# CC2340R5 register map
File version: 1.0
CPU: CM0P 1.0, other endian, MPU, FPU, 3 interrupt priority bits
Registers are 32-bit, read-write, reset 0x0 unless marked. A register's access mark holds for its fields unless they carry their own. Offsets are from the block's base; [hi:lo] are bit positions; {n}, {i} and the like mark numbered series; 'fields as' and 'values as' point back to an identical list.

## PMUD
Base 0x40006000
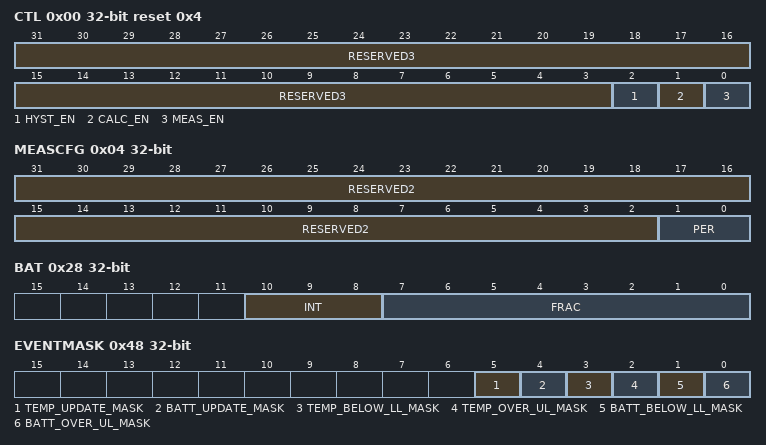
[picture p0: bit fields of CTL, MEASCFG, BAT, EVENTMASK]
0x00 CTL reset 0x4 — Internal. Only to be used through TI provided API.
  [31:3] RESERVED3 ro — [31:3] Internal. Only to be used through TI provided API.
  [2] HYST_EN — [2:2] Internal. Only to be used through TI provided API.
  [1] CALC_EN — [1:1] Internal. Only to be used through TI provided API.
  [0] MEAS_EN — [0:0] Internal. Only to be used through TI provided API.
0x04 MEASCFG — Internal. Only to be used through TI provided API.
  [31:2] RESERVED2 ro — [31:2] Internal. Only to be used through TI provided API.
  [1:0] PER — [1:0] Internal. Only to be used through TI provided API.
    3=_32CYC (Internal. Only to be used through TI provided API.); 2=_16CYC (Internal. Only to be used through TI provided API.); 1=_8CYC (Internal. Only to be used through TI provided API.); 0=CONT (Internal. Only to be used through TI provided API.)
0x08 COMPTEST — Enable BATMON comparator test mode. Note: This register is write-protected based on global lock signal from SYS0 on production devices.
  [0] EN — [0:0] Enable test mode.
    1=ENABLE; 0=DISABLE
0x28 BAT — Last Measured Battery Voltage This register may be read while BATUPD.STAT = 1
  [10:8] INT ro — [10:8] Integer part: 0x0: 0V + fractional part ... 0x3: 3V + fractional part 0x4: 4V + fractional part
  [7:0] FRAC ro — [7:0] Fractional part, standard binary fractional encoding. 0x00: .0V ... 0x20: 1/8 = .125V 0x40: 1/4 = .25V 0x80: 1/2 = .5V ... 0xA0: 1/2 + 1/8 = .625V ... 0xFF: Max
0x2C BATUPD — Battery Update Indicates BAT Updates
  [0] STAT — [0:0] 0: No update since last clear 1: New battery voltage is present. Write 1 to clear the status.
0x30 TEMP — Temperature Last Measured Temperature in Degrees Celsius This register may be read while TEMPUPD.STAT = 1.
  [16:8] INT ro — [16:8] Integer part (signed) of temperature value. Total value = INTEGER + FRACTIONAL 2's complement encoding 0x100: Min value 0x1D8: -40C 0x1FF: -1C 0x00: 0C 0x1B: 27C 0x55: 85C 0xFF: Max value
0x34 TEMPUPD — Temperature Update Indicates TEMP Updates
  [0] STAT — [0:0] 0: No update since last clear 1: New temperature is present. Write 1 to clear the status.
0x38 COMPTESTOUT — BATMON comparator test mode output.
  [0] STAT ro — [0:0] Comparator output in test mode.
    1=HIGH; 0=LOW
0x48 EVENTMASK
  [5] TEMP_UPDATE_MASK — [5:5] 1: EVENT.TEMP_UPDATE contributes to combined event from BATMON 0: EVENT.TEMP_UPDATE does not contribute to combined event from BATMON
  [4] BATT_UPDATE_MASK — [4:4] 1: EVENT.BATT_UPDATE contributes to combined event from BATMON 0: EVENT.BATT_UPDATE does not contribute to combined event from BATMON
  [3] TEMP_BELOW_LL_MASK — [3:3] 1: EVENT.TEMP_BELOW_LL contributes to combined event from BATMON 0: EVENT.TEMP_BELOW_LL does not contribute to combined event from BATMON
  [2] TEMP_OVER_UL_MASK — [2:2] 1: EVENT.TEMP_OVER_UL contributes to combined event from BATMON 0: EVENT.TEMP_OVER_UL does not contribute to combined event from BATMON
  [1] BATT_BELOW_LL_MASK — [1:1] 1: EVENT.BATT_BELOW_LL contributes to combined event from BATMON 0: EVENT.BATT_BELOW_LL does not contribute to combined event from BATMON
  [0] BATT_OVER_UL_MASK — [0:0] 1: EVENT.BATT_OVER_UL contributes to combined event from BATMON 0: EVENT.BATT_OVER_UL does not contribute to combined event from BATMON
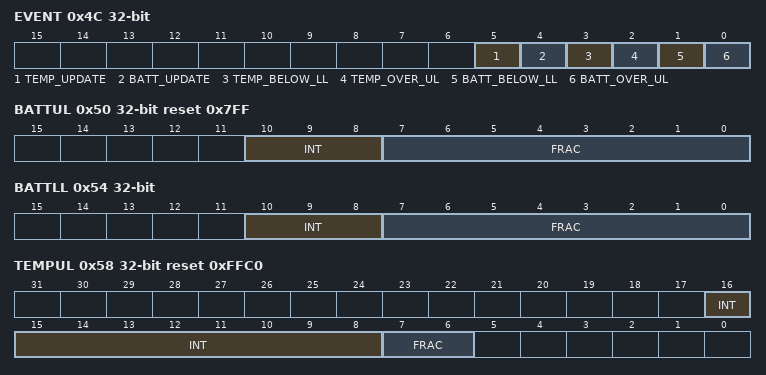
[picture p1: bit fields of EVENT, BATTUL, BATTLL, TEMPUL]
0x4C EVENT
  [5] TEMP_UPDATE — [5:5] Alias to TEMPUPD.STAT
  [4] BATT_UPDATE — [4:4] Alias to BATUPD.STAT
  [3] TEMP_BELOW_LL — [3:3] Read: 1: Temperature level is below the lower limit set by TEMPLL. 0: Temperature level is not below the lower limit set by TEMPLL. Write: 1: Clears the flag 0: No change in the flag
  [2] TEMP_OVER_UL — [2:2] Read: 1: Temperature level is above the upper limit set by TEMPUL. 0: Temperature level is not above the upper limit set by TEMPUL. Write: 1: Clears the flag 0: No change in the flag
  [1] BATT_BELOW_LL — [1:1] Read: 1: Battery level is below the lower limit set by BATTLL. 0: Battery level is not below the lower limit set by BATTLL. Write: 1: Clears the flag 0: No change in the flag
  [0] BATT_OVER_UL — [0:0] Read: 1: Battery level is above the upper limit set by BATTUL. 0: Battery level is not above the upper limit set by BATTUL. Write: 1: Clears the flag 0: No change in the flag
0x50 BATTUL reset 0x7FF — Battery Upper Limit
  [10:8] INT — [10:8] Integer part: 0x0: 0V + fractional part ... 0x3: 3V + fractional part 0x4: 4V + fractional part
  [7:0] FRAC — [7:0] Fractional part, standard binary fractional encoding. 0x00: .0V ... 0x20: 1/8 = .125V 0x40: 1/4 = .25V 0x80: 1/2 = .5V ... 0xA0: 1/2 + 1/8 = .625V ... 0xFF: Max
0x54 BATTLL — Battery Lower Limit
  fields as BATTUL
0x58 TEMPUL reset 0xFFC0 — Temperature Upper Limit
  [16:8] INT — [16:8] Integer part (signed) of temperature upper limit. Total value = INTEGER + FRACTIONAL 2's complement encoding 0x100: Min value 0x1D8: -40C 0x1FF: -1C 0x00: 0C 0x1B: 27C 0x55: 85C 0xFF: Max value
  [7:6] FRAC — [7:6] Fractional part of temperature upper limit. Total value = INTEGER + FRACTIONAL The encoding is an extension of the 2's complement encoding. 00: 0.0C 01: 0.25C 10: 0.5C 11: 0.75C For example: 000000001,00 = ( 1+0,00) = 1,00 000000000,11 = ( 0+0,75) = 0,75 000000000,10 = ( 0+0,50) = 0,50 000000000,01 = ( 0+0,25) = 0,25 000000000,00 = ( 0+0,00) = 0,00 111111111,11 = (-1+0,75) = -0,25 111111111,10 = (-1+0,50) = -0,50 111111111,01 = (-1+0,25) = -0,75 111111111,00 = (-1+0,00) = -1,00 111111110,11 = (-2+0,75) = -1,25
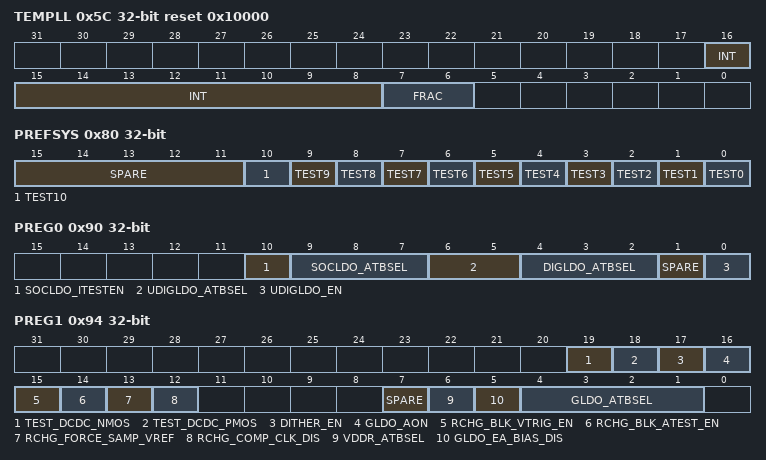
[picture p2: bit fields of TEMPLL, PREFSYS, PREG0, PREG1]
0x5C TEMPLL reset 0x10000 — Temperature Lower Limit
  [16:8] INT — [16:8] Integer part (signed) of temperature lower limit. Total value = INTEGER + FRACTIONAL 2's complement encoding 0x100: Min value 0x1D8: -40C 0x1FF: -1C 0x00: 0C 0x1B: 27C 0x55: 85C 0xFF: Max value
  [7:6] FRAC — [7:6] Fractional part of temperature lower limit. Total value = INTEGER + FRACTIONAL The encoding is an extension of the 2's complement encoding. 00: 0.0C 01: 0.25C 10: 0.5C 11: 0.75C For example: 000000001,00 = ( 1+0,00) = 1,00 000000000,11 = ( 0+0,75) = 0,75 000000000,10 = ( 0+0,50) = 0,50 000000000,01 = ( 0+0,25) = 0,25 000000000,00 = ( 0+0,00) = 0,00 111111111,11 = (-1+0,75) = -0,25 111111111,10 = (-1+0,50) = -0,50 111111111,01 = (-1+0,25) = -0,75 111111111,00 = (-1+0,00) = -1,00 111111110,11 = (-2+0,75) = -1,25
0x80 PREFSYS — PMU REFSYS test register. These test bits connect to PMU REFSYS analog module directly. Note: This register is write-protected except for bits [3:1] based on global lock signal from SYS0 on production devices.
  [15:11] SPARE — [15:11] Spare bits. BATMON comparator enable in test mode is based on COMPTEST.EN bit.
  [10] TEST10 — [10:10] Connects 1uA IPTAT going to BMON to va_atb_pmurefsys_a
    1=SET (Connect); 0=CLR (No connect)
  [9] TEST9 — [9:9] Connects BMON comparator input to va_atb_pmurefsys_a
    1=SET (Connect); 0=CLR (No connect)
  [8] TEST8 — [8:8] Connects BMON comparator output to va_atb_pmurefsys_a
    1=SET (Connect); 0=CLR (No connect)
  [7] TEST7 — [7:7] Connects 0.8V VREF for pmui2v circuit (IREF) to va_atb_pmurefsys_a
    1=SET (Connect); 0=CLR (No connect)
  [6] TEST6 — [6:6] Connects 0.8V VREF for LRF and HFXT to va_atb_pmurefsys_a
    1=SET (Connect); 0=CLR (No connect)
  [5] TEST5 — [5:5] Connects unbuffered bandgap output to va_atb_pmurefsys_a
    1=SET (Connect); 0=CLR (No connect)
  [4] TEST4 — [4:4] Connects buffered bandgap output to va_atb_pmurefsys_a
    1=SET (Connect); 0=CLR (No connect)
  [3] TEST3 — [3:3] Connects 20uA IREF to va_atb_pmurefsys_a
    1=SET (Connect); 0=CLR (No connect)
  [2] TEST2 — [2:2] Connects 1uA IREF to va_atb_pmurefsys_a
    1=SET (Connect); 0=CLR (No connect)
  [1] TEST1 — [1:1] Connects 4uA IREF to va_atb_pmurefsys_a
    1=SET (Connect); 0=CLR (No connect)
  [0] TEST0 — [0:0] Connects 2uA IPTAT to va_atb_pmurefsys_a
    1=SET (Connect); 0=CLR (No connect)
0x90 PREG0 — PMU REG 0 register. Note: All bits in this register except UDIG_LDO_EN are write-protected based on global lock signal from SYS0 on production devices.
  [10] SOCLDO_ITESTEN — [10:10] SOC LDO current test mode enable bit. Needs to be enabled for DIGLDO and UDIGLDO output current testing.
    1=EN (Enable); 0=DIS (Disable)
  [9:7] SOCLDO_ATBSEL — [9:7] SOC LDO ATB selection bits.
    4=VDD_AON (Connect VDD_AON); 2=SOCLDO_VREF_AMP_OUT (Connect reference amplifier output in SOC LDO); 1=SOCLDO_ITEST (Connect selected LDO current output); 0=NC (No test muxes connected)
  [6:5] UDIGLDO_ATBSEL — [6:5] UDIGLDO ATB selection bits. This is used to enable test currents out from UDIGLDO through ATEST.
    3=3/10 of output current; 2=1/5 of output current; 1=1/10 of output current; 0=No currents out
  [4:2] DIGLDO_ATBSEL — [4:2] DIGLDO ATB selection bits. This is used to enable test currents out from DIGLDO through ATEST.
    4=1/60 of output current; 2=1/120 of output current; 1=1/240 of output current; 0=No currents out
  [1] SPARE — [1:1] Spare bit
  [0] UDIGLDO_EN — [0:0] Enable UDIGLDO
    1=EN (Enable); 0=DIS (Disable)
0x94 PREG1 — PMU REG 1 register. Note: All bits in this register except DITHER_EN are write-protected based on global lock signal from SYS0 on production devices.
  [19] TEST_DCDC_NMOS — [19:19] This bit is used to turn on DCDC NMOS switch. TEST_DCDC_PMOS and TEST_DCDC_NMOS bits should not be set together.
    1=EN (Enable); 0=DIS (Disable)
  [18] TEST_DCDC_PMOS — [18:18] This bit is used to turn on DCDC PMOS switch. TEST_DCDC_PMOS and TEST_DCDC_NMOS bits should not be set together.
    1=EN (Enable); 0=DIS (Disable)
  [17] DITHER_EN — [17:17] Enable switching frequency randomizer.
    1=EN (Enable); 0=DIS (Disable)
  [16] GLDO_AON — [16:16] Keep GLDO always on when enabled. PMUDLC cannot disable GLDO pass gate.
    1=EN (Enable); 0=DIS (Disable)
  [15] RCHG_BLK_VTRIG_EN — [15:15] Enable/Disable ATEST input to VDDR input of recharge comparator. Used for trimming the recharge voltage reference level.
    1=EN (Enable); 0=DIS (Disable)
  [14] RCHG_BLK_ATEST_EN — [14:14] Enable/Disable test outputs to recharge comparator block.
    1=EN (Enable); 0=DIS (Disable)
  [13] RCHG_FORCE_SAMP_VREF — [13:13] Force sample of VREF on sample capacitor.
    1=EN (Enable); 0=DIS (Disable)
  [12] RCHG_COMP_CLK_DIS — [12:12] Enable/Disable the 32 kHz clock to the recharge comparator.
    1=DIS (Disable the clock); 0=EN (Enable the clock)
  [7] SPARE — [7:7] Spare bit.
  [6] VDDR_ATBSEL — [6:6] VDDR ATB selection bit. This is used to connect VDDR to ATEST bus. Set GLDO_ATBSEL = 0x0 first before setting this bit.
    1=EN (Connected); 0=DIS (Not connected)
  [5] GLDO_EA_BIAS_DIS — [5:5] Disable GLDO error amplifier bias current
    1=OFF (Bias current is turned off when GLDO is disabled); 0=ON (Bias current remains ON)
  [4:1] GLDO_ATBSEL — [4:1] GLDO ATB selection bits.
    8=VDDROK (VDDR_OK connected to test bus); 4=IB1U (GLDO 1uA bias current connected to test bus); 2=PASSGATE (GLDO pass transistor gate voltage connected to test bus); 1=ERRAMP_OUT (GLDO error amp output voltage connected to test bus); 0=NC (No GLDO signal connected to test bus)
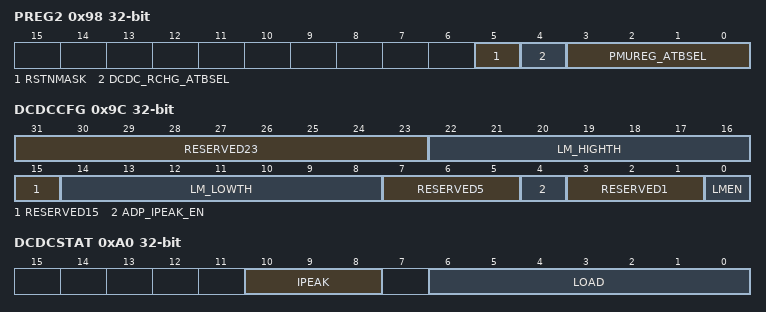
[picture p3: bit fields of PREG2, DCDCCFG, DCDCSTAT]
0x98 PREG2 — PMU REG 2 register. Note: This register is write-protected based on global lock signal from SYS0 on production devices.
  [5] RSTNMASK — [5:5] This bit is used to mask RSTN pin reset during FLTP1 flash test.
    1=MASK (Reset is masked); 0=UNMASK (Reset is unmasked)
  [4] DCDC_RCHG_ATBSEL — [4:4] ATB selection between DCDC/GLDO and Recharge block.
    1=RCHG_BLK (Enables input trigger level test signal to the recharge block); 0=DCDC_GLDO (Enables DCDC/GLDO test signals selected by GLDO_ATBSEL)
  [3:0] PMUREG_ATBSEL — [3:0] PMU REG ATB selection bits.
    8=DCDC_ATEST0_RCHG_ATEST1 (Either DCDC/GLDO or Recharge Block output depending on DCDC_RCHG_ATBSEL bit on ATEST0 and Recharge Block output on ATEST1); 4=SOCLDOI_A0 (SOCLDO current on ATEST0); 2=RESERVED (Do not use); 1=SOCLDOV_A1 (SOCLDO voltage on ATEST1); 0=NC (No signal connected to ATEST outputs)
0x9C DCDCCFG — Internal. Only to be used through TI provided API.
  [31:23] RESERVED23 ro — [31:23] Internal. Only to be used through TI provided API.
  [22:16] LM_HIGHTH — [22:16] Internal. Only to be used through TI provided API.
    127=MAX (Internal. Only to be used through TI provided API.); 0=MIN (Internal. Only to be used through TI provided API.)
  [15] RESERVED15 ro — [15:15] Internal. Only to be used through TI provided API.
  [14:8] LM_LOWTH — [14:8] Internal. Only to be used through TI provided API.
    values as LM_HIGHTH
  [7:5] RESERVED5 ro — [7:5] Internal. Only to be used through TI provided API.
  [4] ADP_IPEAK_EN — [4:4] Internal. Only to be used through TI provided API.
    1=ENABLE (Internal. Only to be used through TI provided API.); 0=DISABLE (Internal. Only to be used through TI provided API.)
  [3:1] RESERVED1 ro — [3:1] Internal. Only to be used through TI provided API.
  [0] LMEN — [0:0] Internal. Only to be used through TI provided API.
    values as ADP_IPEAK_EN
0xA0 DCDCSTAT — DCDC status register
  [10:8] IPEAK ro — [10:8] DCDC IPEAK value. This value is same as what is programmed in SYS0.TDCDC.IPEAK when adaptive IPEAK adjustment scheme is not enabled and it shows current IPEAK value applied by hardware when adaptive IPEAK adjustment scheme is enabled.
    7=MAX (Maximum value); 0=MIN (Minimum value)
  [6:0] LOAD ro — [6:0] This indicates DCDC load meter output value in percentage scale. Valid range is 0x1 to 0x64.
    127=MAX (Maximum value); 0=MIN (Minimum value)
0xF8 DTBBATMON — BATMON DTB MUX selection signal
  [4:0] SEL — [4:0] DTB MUX selection signal
    {v}=GRP{v} (GRP{v} DTB outputs) (v=1..15); 0=DISABLE (All DTB outputs driven to zero)
0xFC DTBDCDC — DCDC DTB MUX selection signal
  [2:0] SEL — [2:0] DCDC DTB MUX selection signal
    7=GRP7 (GRP7 DTB outputs); 6=GRP6 (GRP6 DTB outputs); 5=GRP5 (GRP5 DTB outputs); 4=GRP4 (GRP 4 DTB outputs); 3=GRP3 (GRP3 DTB outputs); 2=GRP2 (GRP2 DTB outputs); 1=GRP1 (GRP1 DTB outputs); 0=DISABLE (All DTB outputs driven to zero)
